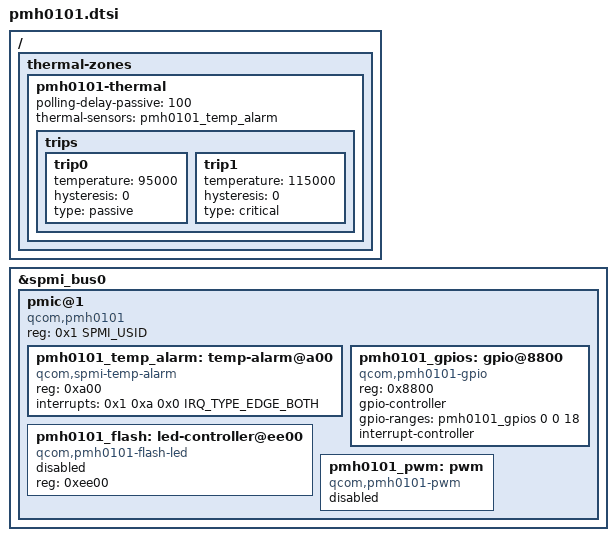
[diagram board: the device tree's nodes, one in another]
// SPDX-License-Identifier: BSD-3-Clause
/*
 * Copyright (c) Qualcomm Technologies, Inc. and/or its subsidiaries.
 */

#include <dt-bindings/interrupt-controller/irq.h>
#include <dt-bindings/spmi/spmi.h>

/ {
	thermal-zones {
		pmh0101-thermal {
			polling-delay-passive = <100>;
			thermal-sensors = <&pmh0101_temp_alarm>;

			trips {
				trip0 {
					temperature = <95000>;
					hysteresis = <0>;
					type = "passive";
				};

				trip1 {
					temperature = <115000>;
					hysteresis = <0>;
					type = "critical";
				};
			};
		};
	};
};

&spmi_bus0 {
	pmic@1 {
		compatible = "qcom,pmh0101", "qcom,spmi-pmic";
		reg = <0x1 SPMI_USID>;
		#address-cells = <1>;
		#size-cells = <0>;

		pmh0101_temp_alarm: temp-alarm@a00 {
			compatible = "qcom,spmi-temp-alarm";
			reg = <0xa00>;
			interrupts = <0x1 0xa 0x0 IRQ_TYPE_EDGE_BOTH>;
			#thermal-sensor-cells = <0>;
		};

		pmh0101_gpios: gpio@8800 {
			compatible = "qcom,pmh0101-gpio", "qcom,spmi-gpio";
			reg = <0x8800>;
			gpio-controller;
			gpio-ranges = <&pmh0101_gpios 0 0 18>;
			#gpio-cells = <2>;
			interrupt-controller;
			#interrupt-cells = <2>;
		};

		pmh0101_flash: led-controller@ee00 {
			compatible = "qcom,pmh0101-flash-led", "qcom,spmi-flash-led";
			reg = <0xee00>;
			status = "disabled";
		};

		pmh0101_pwm: pwm {
			compatible = "qcom,pmh0101-pwm", "qcom,pm8350c-pwm";
			#pwm-cells = <2>;
			status = "disabled";
		};
	};
};
